# STM32H573 register map
File version: 1.7
CPU: CM33 r0p0, little endian, MPU, FPU, 4 interrupt priority bits
Registers are 32-bit, read-write, reset 0x0 unless marked. A register's access mark holds for its fields unless they carry their own. Offsets are from the block's base; [hi:lo] are bit positions; {n}, {i} and the like mark numbered series; 'fields as' and 'values as' point back to an identical list.

## OTFDEC1 — On-The-Fly Decryption engine
Base 0x46005000
Same registers: SEC_OTFDEC1 0x56005000
0x00 OTFDEC_CR — OTFDEC control register
  [0] ENC — Encryption mode bit When this bit is set, OTFDEC is used in encryption mode, during which application can write clear text data then read back encrypted data. When this bit is cleared (default), OTFDEC is used in decryption mode, during which application only read back decrypted data. For both modes, cryptographic context (keys, nonces, firmware versions) must be properly initialized. When this bit is set, only data accesses are allowed (zeros are returned otherwise, and XONEIF is set). When MODE = 11, enhanced encryption mode is automatically selected. Note: When ENC bit is set, no access to OCTOSPI must be done (registers and Memory mapped region).
    0=OTFDEC working in decryption mode; 1=OTFDEC working in encryption mode
0x10 OTFDEC_PRIVCFGR
  [0] PRIV — Privileged access protection. Unprivileged read accesses to registers return zeros Unprivileged write accesses to registers are ignored. Note: This bit can only be written in privileged mode. There is no limitations on reads.
    0=No additional protection is added on OTFDEC register accesses; 1=An additional protection is added when accessing all registers except OTFDEC_PRIVCFGR:
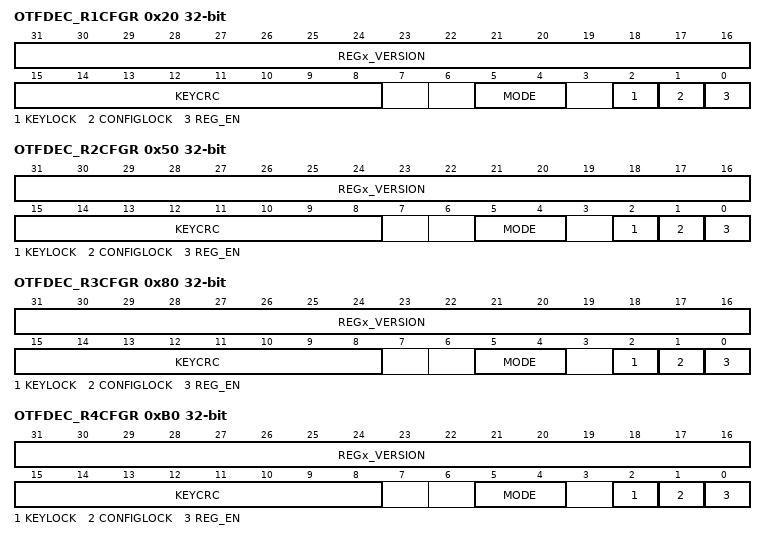
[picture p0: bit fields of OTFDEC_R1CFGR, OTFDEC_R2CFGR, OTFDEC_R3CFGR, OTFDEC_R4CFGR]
0x20 OTFDEC_R1CFGR access per field — OTFDEC region 1 configuration register
  [31:16] REGx_VERSION rw — region firmware version This 16-bit bitfield must be correctly initialized before the region corresponding REG_EN bit is set in OTFDEC_RxCFGR.
  [15:8] KEYCRC ro — region key 8-bit CRC When KEYLOCK = 0, KEYCRC bitfield is automatically computed by hardware while loading the key of this region in this exact sequence: KEYR0 then KEYR1 then KEYR2 then finally KEYR3 (all written once). A new computation starts as soon as a new valid sequence is initiated, and KEYCRC is read as zero until a valid sequence is completed. When KEYLOCK = 1, KEYCRC remains unchanged until the next reset. CRC computation is an 8-bit checksum using the standard CRC-8-CCITT algorithm X8 + X2 + X + 1 (according the convention). Source code is available in . This field is read only. Note: CRC information is updated only after the last bit of the key has been written.
  [5:4] MODE rw — operating mode This bitfield selects the OTFDEC operating mode for this region: Others: Reserved When MODE different 11, the standard AES encryption mode is activated. When either of the MODE bits are changed, the region key and associated CRC are zeroed.
    2=All read accesses are decrypted (instruction or data); 3=Enhanced encryption mode is activated, and only instruction accesses are decrypted
  [2] KEYLOCK rw — region key lock Note: This bit is set once: if this bit is set, it can only be reset to 0 if the OTFDEC is reset.
    0=Writes to this region KEYRx registers are allowed; 1=Writes to this region KEYRx registers are ignored until next OTFDEC reset. KEYCRC bitfield is locked.
  [1] CONFIGLOCK rw — region config lock Note: This bit is set once. If this bit is set, it can only be reset to 0 if OTFDEC is reset. Setting this bit forces KEYLOCK bit to 1.
    0=Writes to this region OTFDEC_RxCFGR, OTFDEC_RxSTARTADDR, OTFDEC_RxENDADDR and OTFDEC_RxNONCERy registers are allowed; 1=Writes to this region OTFDEC_RxCFGR, OTFDEC_RxSTARTADDR, OTFDEC_RxENDADDR and OTFDEC_RxNONCERy registers are ignored until next OTFDEC reset
  [0] REG_EN rw — region on-the-fly decryption enable Note: Garbage is decrypted if region context (version, key, nonce) is not valid when this bit is set.
    0=On-the-fly decryption is disabled for this region; 1=On-the-fly decryption is enabled for this region. Data are XORed with the corresponding keystream.
0x24 OTFDEC_R1STARTADDR — OTFDEC region 1 start address register
  [31:0] REGx_START_ADDR — Region AHB start address This register must be written before the region corresponding REG_EN bit in the OTFDEC_RxCFGR register is set. Writing to this register is discarded if performed while the region CONFIGLOCK bit in the OTFDEC_RxCFGR register is set. Note: When determining the region the first 12 bits (lsb) and the last 4 bits (msb) are ignored. When this register is accessed in read the 4 msb bits and the 12 lsb bits return zeros .
0x28 OTFDEC_R1ENDADDR reset 0xFFF — OTFDEC region 1 end address register
  [31:0] REGx_END_ADDR — Region AHB end address This register must be written before the region corresponding REG_EN bit in the OTFDEC_RxCFGR register is set, and OTFDEC_RxENDADDR must be strictly greater than OTFDEC_RxSTARTADDR to be valid. Writing to this register is discarded if performed while the region CONFIGLOCK bit in OTFDEC_RxCFGR is set. Note: When determining the region the first 12 bits (lsb) and the last 4 bits (msb) are ignored. When this register is accessed in read the 4 msb bits return zeros and the 12 lsb bits return ones.
0x2C OTFDEC_R1NONCER0 — OTFDEC region 1 nonce register 0
  [31:0] REGx_NONCE — Region nonce, bits [31:0] This register must be written before the region corresponding REG_EN bit in OTFDEC_RxCFGR is set. Writing is discarded in this register if performed while the region CONFIGLOCK bit in the OTFDEC_RxCFGR is set.
{0x0+0x30*i} OTFDEC_R{i}NONCER1 (i=1..4) — OTFDEC region {i} nonce register 1
  [31:0] REGx_NONCE — Region nonce, bits [63:32] Refer to the OTFDEC_RxNONCER0 register for description of the NONCE[63:0] bitfield.
{0x4+0x30*i} OTFDEC_R{i}KEYR0 wo (i=1..4) — OTFDEC region {i} key register 0
  [31:0] REGx_KEY — Region key, bits [31:0] This register must be written before the region corresponding REG_EN bit in OTFDEC_RxCFGR is set. Reading this register returns a zero value. Writing to this register is discarded if performed while the region CONFIGLOCK or KEYLOCK bit is set in the OTFDEC_RxCFGR. Note: When application successfully changes MODE bits in OTFDEC_RxCFGR and OTFDEC_RxKEYR, and associated KEYCRC are erased.
{0x8+0x30*i} OTFDEC_R{i}KEYR1 wo (i=1..4) — OTFDEC region {i} key register 1
  [31:0] REGx_KEY — Region key, bits [63:32] Refer to the OTFDEC_RxKEYR0 register for description of the KEY[127:0] bitfield.
{0xC+0x30*i} OTFDEC_R{i}KEYR2 wo (i=1..4) — OTFDEC region {i} key register 2
  [31:0] REGx_KEY — Region key, bits [95:64] Refer to the OTFDEC_RxKEYR0 register for description of the KEY[127:0] bitfield.
{0x10+0x30*i} OTFDEC_R{i}KEYR3 wo (i=1..4) — OTFDEC region {i} key register 3
  [31:0] REGx_KEY — Region key, bits [127:96] Refer to the OTFDEC_RxKEYR0 register for description of the KEY[127:0] bitfield.
0x50 OTFDEC_R2CFGR access per field — OTFDEC region 2 configuration register
  fields as OTFDEC_R1CFGR
0x54 OTFDEC_R2STARTADDR — OTFDEC region 2 start address register
  fields as OTFDEC_R1STARTADDR
0x58 OTFDEC_R2ENDADDR reset 0xFFF — OTFDEC region 2 end address register
  fields as OTFDEC_R1ENDADDR
0x5C OTFDEC_R2NONCER0 — OTFDEC region 2 nonce register 0
  fields as OTFDEC_R1NONCER0
0x80 OTFDEC_R3CFGR access per field — OTFDEC region 3 configuration register
  fields as OTFDEC_R1CFGR
0x84 OTFDEC_R3STARTADDR — OTFDEC region 3 start address register
  fields as OTFDEC_R1STARTADDR
0x88 OTFDEC_R3ENDADDR reset 0xFFF — OTFDEC region 3 end address register
  fields as OTFDEC_R1ENDADDR
0x8C OTFDEC_R3NONCER0 — OTFDEC region 3 nonce register 0
  fields as OTFDEC_R1NONCER0
0xB0 OTFDEC_R4CFGR access per field — OTFDEC region 4 configuration register
  fields as OTFDEC_R1CFGR
0xB4 OTFDEC_R4STARTADDR — OTFDEC region 4 start address register
  fields as OTFDEC_R1STARTADDR
0xB8 OTFDEC_R4ENDADDR reset 0xFFF — OTFDEC region 4 end address register
  fields as OTFDEC_R1ENDADDR
0xBC OTFDEC_R4NONCER0 — OTFDEC region 4 nonce register 0
  fields as OTFDEC_R1NONCER0
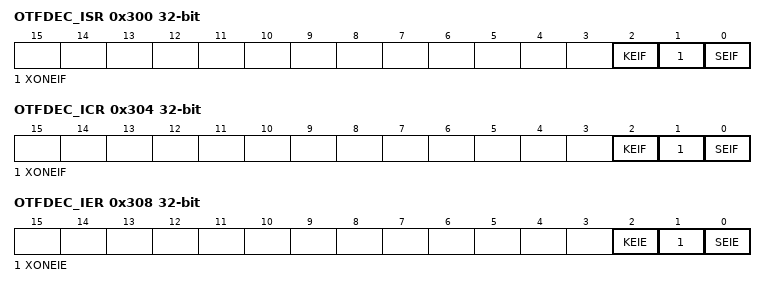
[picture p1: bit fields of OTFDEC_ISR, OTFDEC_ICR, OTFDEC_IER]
0x300 OTFDEC_ISR ro — OTFDEC interrupt status register
  [2] KEIF — Key error interrupt flag status This bit is set by hardware and read only by application. The bit is set when a read access occurs on an encrypted region, while its key registers is null or not properly initialized (KEYCRC = 0x0). This bit is cleared when the application sets in OTFDEC_ICR the corresponding bit to 1. After KEIF is set any subsequent read to the region with bad key registers returns a zeroed value. This state remains until those key registers are properly initialized (KEYCRC not zero).
    0=OTFDEC operates properly; 1=Read access detected on an enabled encrypted region with its key registers null or not properly initialized (KEYCRC = 0x0). OTFDEC returns a zeroed value for the read, and an optional interrupt is generated if bit KEIE is set to 1 in OTFDEC_IER.
  [1] XONEIF — Execute-only execute-never error interrupt flag status This bit is set by hardware and read only by application. This bit is set when a read access and not an instruction fetch is detected on any encrypted region with MODE bits set to 11. Lastly, XONEIF is also set when an execute access is detected while encryption mode is enabled. This bit is cleared when application sets in OTFDEC_ICR the corresponding bit to 1.
    0=No execute-only error status. No interrupt pending.; 1=Read access detected on one region with MODE bits set to 11 or execute access detected while ENC = 1. OTFDEC returns a zeroed value for the illegal access, and an optional interrupt is generated if bit XONEIE is set to 1 in OTFDEC_IER.
  [0] SEIF — Security error interrupt flag status This bit is set by hardware and read only by application. This bit is set when at least one security error has been detected. This bit is cleared when application sets in OTFDEC_ICR the corresponding bit to 1.
    0=No security error status. No interrupt pending.; 1=Security error flag status, with interrupt pending. Actual interrupt generation is dependent on OTFDEC_IER corresponding bit SEIE.
0x304 OTFDEC_ICR wo — OTFDEC interrupt clear register
  [2] KEIF — Key error interrupt flag clear This bit is written by application, and always read as 0. Note: Clearing KEIF does not solve the source of the problem (bad key registers). To be able to access again any encrypted region, OTFDEC key registers must be properly initialized again.
    0=KEIF flag status is not affected; 1=KEIF flag status is cleared in OTFDEC_ISR
  [1] XONEIF — Execute-only execute-never error interrupt flag clear This bit is written by application, and always read as 0.
    0=XONEIF flag status is not affected; 1=XONEIF flag status is cleared in OTFDEC_ISR
  [0] SEIF — Security error interrupt flag clear This bit is written by application, and always read as 0.
    0=SEIF flag status is not affected; 1=SEIF flag status is cleared in OTFDEC_ISR
0x308 OTFDEC_IER — OTFDEC interrupt enable register
  [2] KEIE — Key error interrupt enable This bit is read and written by application. It controls the OTFDEC interrupt generation when KEIF flag status is set.
    0=Interrupt generation on key error flag KEIF is disabled (masked); 1=Interrupt generation on key error flag KEIF is enabled (not masked)
  [1] XONEIE — Execute-only execute-never error interrupt enable This bit is read and written by application. It controls the OTFDEC interrupt generation when XONEIF flag status is set.
    0=Interrupt generation on execute-only error XONEIF is disabled (masked); 1=Interrupt generation on execute-only error XONEIF is enabled (not masked)
  [0] SEIE — Security error interrupt enable This bit is read and written by application. It controls the OTFDEC interrupt generation when SEIF flag status is set.
    0=Interrupt generation on security error SEIF is disabled (masked); 1=Interrupt generation on security error SEIF is enabled (not masked)
